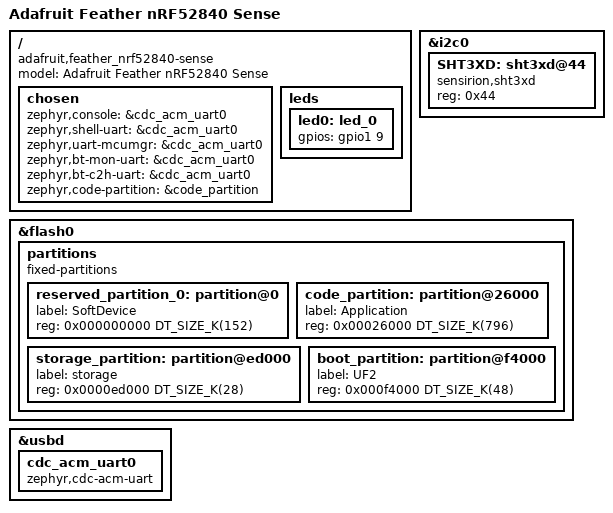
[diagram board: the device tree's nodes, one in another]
/*
 * Copyright (c) 2020 Tobias Svehagen
 * Copyright (c) 2024 Jacob Winther
 *
 * SPDX-License-Identifier: Apache-2.0
 */

/dts-v1/;
#include "adafruit_feather_nrf52840_common.dtsi"

/ {
	model = "Adafruit Feather nRF52840 Sense";
	compatible = "adafruit,feather_nrf52840-sense";

	chosen {
		zephyr,console = &cdc_acm_uart0;
		zephyr,shell-uart = &cdc_acm_uart0;
		zephyr,uart-mcumgr = &cdc_acm_uart0;
		zephyr,bt-mon-uart = &cdc_acm_uart0;
		zephyr,bt-c2h-uart = &cdc_acm_uart0;
		zephyr,code-partition = &code_partition;
	};

	leds {
		led0: led_0 {
			gpios = <&gpio1 9 0>;
		};
	};
};

&i2c0 {
	SHT3XD: sht3xd@44 {
		compatible = "sensirion,sht3xd";
		reg = <0x44>;
	};
};

&flash0 {
	partitions {
		compatible = "fixed-partitions";
		#address-cells = <1>;
		#size-cells = <1>;

		/* To enable flashing with UF2 bootloader, we
		 * must reserve a partition for SoftDevice.
		 * See https://learn.adafruit.com/
		 *     introducing-the-adafruit-nrf52840-feather?view=all#hathach-memory-map
		 */
		reserved_partition_0: partition@0 {
			label = "SoftDevice";
			reg = <0x000000000 DT_SIZE_K(152)>;
		};
		code_partition: partition@26000 {
			label = "Application";
			reg = <0x00026000 DT_SIZE_K(796)>;
		};

		/*
		 * The flash starting at 0x000ed000 and ending at
		 * 0x000f4000 is reserved for use by the application.
		 */
		storage_partition: partition@ed000 {
			label = "storage";
			reg = <0x0000ed000 DT_SIZE_K(28)>;
		};

		boot_partition: partition@f4000 {
			label = "UF2";
			reg = <0x000f4000 DT_SIZE_K(48)>;
		};
	};
};

zephyr_udc0: &usbd {
	cdc_acm_uart0: cdc_acm_uart0 {
		compatible = "zephyr,cdc-acm-uart";
	};
};
